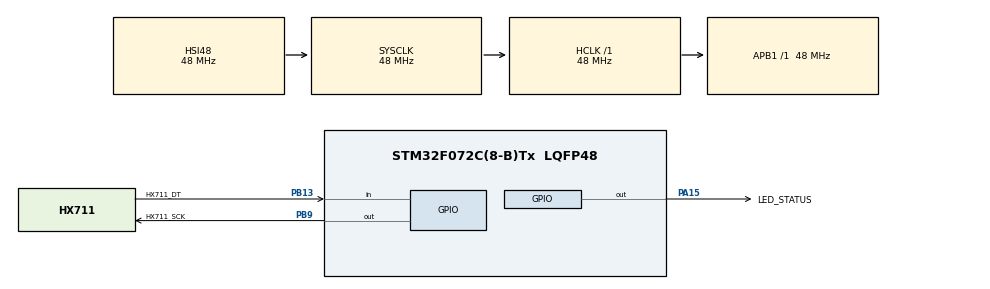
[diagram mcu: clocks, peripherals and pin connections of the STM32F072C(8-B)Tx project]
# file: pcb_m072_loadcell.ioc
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Mcu.Family=STM32F0
Mcu.Name=STM32F072C(8-B)Tx
Mcu.Package=LQFP48
PA13.Mode=Serial_Wire
PA13.Signal=SYS_SWDIO
PA14.Mode=Serial_Wire
PA14.Signal=SYS_SWCLK
PA15.GPIO_Label=LED_STATUS
PA15.Signal=GPIO_Output
PB13.GPIO_Label=HX711_DT
PB13.Signal=GPIO_Input
PB9.GPIO_Label=HX711_SCK
PB9.Signal=GPIO_Output
PF0-OSC_IN.Mode=HSE-External-Oscillator
PF0-OSC_IN.Signal=RCC_OSC_IN
PF1-OSC_OUT.Mode=HSE-External-Oscillator
PF1-OSC_OUT.Signal=RCC_OSC_OUT
ProjectManager.HeapSize=0x200
ProjectManager.StackSize=0x400
ProjectManager.TargetToolchain=STM32CubeIDE
RCC.AHBFreq_Value=48000000
RCC.APB1Freq_Value=48000000
RCC.APB1TimFreq_Value=48000000
RCC.HCLKFreq_Value=48000000
RCC.SYSCLKFreq_VALUE=48000000
RCC.SYSCLKSource=RCC_SYSCLKSOURCE_HSI48
TIM2.Prescaler=47
VP_TIM2_VS_ClockSourceINT.Mode=Internal
board=custom

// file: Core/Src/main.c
/* USER CODE BEGIN Header */
/**
  ******************************************************************************
  * @file           : main.c
  * @brief          : Main program body
  ******************************************************************************
  * @attention
  *
  * Copyright (c) 2025 STMicroelectronics.
  * All rights reserved.
  *
  * This software is licensed under terms that can be found in the LICENSE file
  * in the root directory of this software component.
  * If no LICENSE file comes with this software, it is provided AS-IS.
  *
  ******************************************************************************
  */
/* USER CODE END Header */
#include "main.h"
#include <stdbool.h> // Include for boolean types

/* USER CODE BEGIN PD */
#define DT_PORT GPIOB
#define DT_PIN GPIO_PIN_13
#define SCK_PORT GPIOB
#define SCK_PIN GPIO_PIN_9

#define NUM_SAMPLES 32 // Number of samples to average for a stable reading
/* USER CODE END PD */

TIM_HandleTypeDef htim2;

/* USER CODE BEGIN PV */
// --- HX711 State and Data Variables ---
static long tare_offset = 0;
// IMPORTANT: You must determine this calibration factor yourself!
// See the "How to Calibrate" section below. A value of 420.0 is a common starting point.
static float calibration_factor = 837.0;

volatile long current_weight_mg = 0;
volatile bool new_weight_available = false;

// Non-blocking state machine variables
typedef enum {
    HX711_IDLE,
    HX711_WAIT_FOR_READY,
    HX711_READING_BITS
} HX711_State;

static HX711_State hx711_state = HX711_IDLE;
static uint32_t raw_data_buffer = 0;
static uint8_t bit_counter = 0;
static long sample_accumulator = 0;
static uint8_t sample_counter = 0;
/* USER CODE END PV */

void SystemClock_Config(void);
static void MX_GPIO_Init(void);
static void MX_TIM2_Init(void);
/* USER CODE BEGIN PFP */
void microDelay(uint16_t delay);
long Read_HX711_Raw(void);
void HX711_Tare(void);
void HX711_Manager(void);
/* USER CODE END PFP */

/* USER CODE BEGIN 0 */

void microDelay(uint16_t delay) {
    __HAL_TIM_SET_COUNTER(&htim2, 0);
    while (__HAL_TIM_GET_COUNTER(&htim2) < delay);
}

/**
  * @brief  Reads a single raw value from the HX711. This is a blocking function.
  * @note   This function is only used during initialization (Tare).
  * The main loop uses the non-blocking manager.
  * @retval The 24-bit raw ADC value.
  */
long Read_HX711_Raw(void) {
    long data = 0;
    uint32_t start_time = HAL_GetTick();

    // 1. Wait for the HX711 to become ready (DT pin goes LOW)
    while (HAL_GPIO_ReadPin(DT_PORT, DT_PIN) == GPIO_PIN_SET) {
        if (HAL_GetTick() - start_time > 200) { // Timeout
            return 0;
        }
    }

    // 2. Read the 24 bits of data
    for (uint8_t i = 0; i < 24; i++) {
        HAL_GPIO_WritePin(SCK_PORT, SCK_PIN, GPIO_PIN_SET);
        microDelay(1);
        data = data << 1;
        HAL_GPIO_WritePin(SCK_PORT, SCK_PIN, GPIO_PIN_RESET);
        microDelay(1);
        if (HAL_GPIO_ReadPin(DT_PORT, DT_PIN) == GPIO_PIN_SET) {
            data++;
        }
    }

    // 3. Send 1 clock pulse to set gain to 128 for the next reading
    HAL_GPIO_WritePin(SCK_PORT, SCK_PIN, GPIO_PIN_SET);
    microDelay(1);
    HAL_GPIO_WritePin(SCK_PORT, SCK_PIN, GPIO_PIN_RESET);
    microDelay(1);

    // 4. Convert from 24-bit two's complement to 32-bit signed long
    data = data ^ 0x800000;

    return data;
}

/**
  * @brief  Performs a tare operation by reading the sensor multiple times
  * to get a stable zero-offset.
  * @note   Ensure NO LOAD is on the scale when this is called.
  */
void HX711_Tare(void) {
    long total = 0;
    // Let the ADC settle
    for (int i = 0; i < 5; i++) {
        Read_HX711_Raw();
        HAL_Delay(10);
    }
    // Average several readings for a stable tare value
    for (int i = 0; i < NUM_SAMPLES; i++) {
        total += Read_HX711_Raw();
        HAL_Delay(10);
    }
    tare_offset = total / NUM_SAMPLES;
}

/**
  * @brief  Non-blocking state machine to manage HX711 readings.
  * @note   Call this function repeatedly in your main while loop.
  */
void HX711_Manager(void) {
    switch (hx711_state) {
        case HX711_IDLE:
            // If the HX711 is ready for a new reading, start the process
            if (HAL_GPIO_ReadPin(DT_PORT, DT_PIN) == GPIO_PIN_RESET) {
                raw_data_buffer = 0;
                bit_counter = 0;
                hx711_state = HX711_READING_BITS;
            }
            break;

        case HX711_WAIT_FOR_READY: // This state is now implicitly handled by HX711_IDLE
            // Kept for conceptual clarity, but the logic is merged into IDLE
            break;

        case HX711_READING_BITS:
            // Pulse the clock high
            HAL_GPIO_WritePin(SCK_PORT, SCK_PIN, GPIO_PIN_SET);
            microDelay(1);

            // Shift and read the bit
            raw_data_buffer = raw_data_buffer << 1;
            if (HAL_GPIO_ReadPin(DT_PORT, DT_PIN) == GPIO_PIN_SET) {
                raw_data_buffer++;
            }

            // Pulse the clock low
            HAL_GPIO_WritePin(SCK_PORT, SCK_PIN, GPIO_PIN_RESET);
            microDelay(1);

            bit_counter++;

            // Check if all 24 bits have been read
            if (bit_counter >= 24) {
                // Send the final clock pulse to set gain for the next reading
                HAL_GPIO_WritePin(SCK_PORT, SCK_PIN, GPIO_PIN_SET);
                microDelay(1);
                HAL_GPIO_WritePin(SCK_PORT, SCK_PIN, GPIO_PIN_RESET);
                microDelay(1);

                // Convert to signed value and add to accumulator
                long final_data = (long)(raw_data_buffer ^ 0x800000);
                sample_accumulator += final_data;
                sample_counter++;

                // Reset for the next reading cycle
                hx711_state = HX711_IDLE;
            }
            break;
    }

    // Check if we have collected enough samples to calculate a weight
    if (sample_counter >= NUM_SAMPLES) {
        long average_raw = sample_accumulator / NUM_SAMPLES;

        // Calculate the final weight
        current_weight_mg = (long)(((float)average_raw - (float)tare_offset) / calibration_factor);
//        current_weight_mg = average_raw - tare_offset; //for calibration only
        new_weight_available = true; // Set flag for the main loop

        // Reset for the next averaging cycle
        sample_accumulator = 0;
        sample_counter = 0;
    }
}

/* USER CODE END 0 */

int main(void)
{

  /* MCU Configuration--------------------------------------------------------*/
  HAL_Init();
  SystemClock_Config();
  MX_GPIO_Init();
  MX_TIM2_Init();

  /* USER CODE BEGIN 2 */
  HAL_TIM_Base_Start(&htim2);

  // Power up sequence for HX711
  HAL_GPIO_WritePin(SCK_PORT, SCK_PIN, GPIO_PIN_RESET);
  HAL_Delay(10);

  // Tare the scale at startup. Make sure nothing is on the scale!
  HX711_Tare();
  HAL_Delay(1500);
  HX711_Tare();
  /* USER CODE END 2 */

  /* Infinite loop */
  /* USER CODE BEGIN WHILE */
  while (1)
  {
    // Continuously run the non-blocking manager
    HX711_Manager();

    // Check if a new, averaged weight reading is ready
    if (new_weight_available) {
      new_weight_available = false; // Clear the flag

      // You can now use the `current_weight_mg` variable.
      // For example, print it via UART, display it on an LCD, etc.
      // NOTE: For debugging, you can set a breakpoint here to check the value.
      __NOP(); // No operation, a good place for a breakpoint
    }

    // You can add other non-blocking tasks here.
    // For example, blinking an LED.
    // HAL_GPIO_TogglePin(GPIOA, GPIO_PIN_5); // Example for NUCLEO-F0 board LED
    // HAL_Delay(100); // Small delay to prevent the loop from hogging CPU

    /* USER CODE END WHILE */

  }
}

void SystemClock_Config(void)
{
  RCC_OscInitTypeDef RCC_OscInitStruct = {0};
  RCC_ClkInitTypeDef RCC_ClkInitStruct = {0};

  /** Initializes the RCC Oscillators according to the specified parameters
  * in the RCC_OscInitTypeDef structure.
  */
  RCC_OscInitStruct.OscillatorType = RCC_OSCILLATORTYPE_HSI48;
  RCC_OscInitStruct.HSI48State = RCC_HSI48_ON;
  RCC_OscInitStruct.PLL.PLLState = RCC_PLL_NONE;
  if (HAL_RCC_OscConfig(&RCC_OscInitStruct) != HAL_OK)
  {
    Error_Handler();
  }

  /** Initializes the CPU, AHB and APB buses clocks
  */
  RCC_ClkInitStruct.ClockType = RCC_CLOCKTYPE_HCLK|RCC_CLOCKTYPE_SYSCLK
                              |RCC_CLOCKTYPE_PCLK1;
  RCC_ClkInitStruct.SYSCLKSource = RCC_SYSCLKSOURCE_HSI48;
  RCC_ClkInitStruct.AHBCLKDivider = RCC_SYSCLK_DIV1;
  RCC_ClkInitStruct.APB1CLKDivider = RCC_HCLK_DIV1;

  if (HAL_RCC_ClockConfig(&RCC_ClkInitStruct, FLASH_LATENCY_1) != HAL_OK)
  {
    Error_Handler();
  }
}

static void MX_TIM2_Init(void)
{

  TIM_ClockConfigTypeDef sClockSourceConfig = {0};
  TIM_MasterConfigTypeDef sMasterConfig = {0};

  htim2.Instance = TIM2;
  htim2.Init.Prescaler = 47;
  htim2.Init.CounterMode = TIM_COUNTERMODE_UP;
  htim2.Init.Period = 4294967295;
  htim2.Init.ClockDivision = TIM_CLOCKDIVISION_DIV1;
  htim2.Init.AutoReloadPreload = TIM_AUTORELOAD_PRELOAD_DISABLE;
  if (HAL_TIM_Base_Init(&htim2) != HAL_OK)
  {
    Error_Handler();
  }
  sClockSourceConfig.ClockSource = TIM_CLOCKSOURCE_INTERNAL;
  if (HAL_TIM_ConfigClockSource(&htim2, &sClockSourceConfig) != HAL_OK)
  {
    Error_Handler();
  }
  sMasterConfig.MasterOutputTrigger = TIM_TRGO_RESET;
  sMasterConfig.MasterSlaveMode = TIM_MASTERSLAVEMODE_DISABLE;
  if (HAL_TIMEx_MasterConfigSynchronization(&htim2, &sMasterConfig) != HAL_OK)
  {
    Error_Handler();
  }

}

static void MX_GPIO_Init(void)
{
  GPIO_InitTypeDef GPIO_InitStruct = {0};

  /* GPIO Ports Clock Enable */
  __HAL_RCC_GPIOF_CLK_ENABLE();
  __HAL_RCC_GPIOB_CLK_ENABLE();
  __HAL_RCC_GPIOA_CLK_ENABLE();

  /*Configure GPIO pin Output Level */
  HAL_GPIO_WritePin(LED_STATUS_GPIO_Port, LED_STATUS_Pin, GPIO_PIN_RESET);

  /*Configure GPIO pin Output Level */
  HAL_GPIO_WritePin(HX711_SCK_GPIO_Port, HX711_SCK_Pin, GPIO_PIN_RESET);

  /*Configure GPIO pin : HX711_DT_Pin */
  GPIO_InitStruct.Pin = HX711_DT_Pin;
  GPIO_InitStruct.Mode = GPIO_MODE_INPUT;
  GPIO_InitStruct.Pull = GPIO_NOPULL;
  HAL_GPIO_Init(HX711_DT_GPIO_Port, &GPIO_InitStruct);

  /*Configure GPIO pin : LED_STATUS_Pin */
  GPIO_InitStruct.Pin = LED_STATUS_Pin;
  GPIO_InitStruct.Mode = GPIO_MODE_OUTPUT_PP;
  GPIO_InitStruct.Pull = GPIO_NOPULL;
  GPIO_InitStruct.Speed = GPIO_SPEED_FREQ_LOW;
  HAL_GPIO_Init(LED_STATUS_GPIO_Port, &GPIO_InitStruct);

  /*Configure GPIO pin : HX711_SCK_Pin */
  GPIO_InitStruct.Pin = HX711_SCK_Pin;
  GPIO_InitStruct.Mode = GPIO_MODE_OUTPUT_PP;
  GPIO_InitStruct.Pull = GPIO_NOPULL;
  GPIO_InitStruct.Speed = GPIO_SPEED_FREQ_LOW;
  HAL_GPIO_Init(HX711_SCK_GPIO_Port, &GPIO_InitStruct);

}

void Error_Handler(void)
{
  __disable_irq();
  while (1)
  {
  }
}
